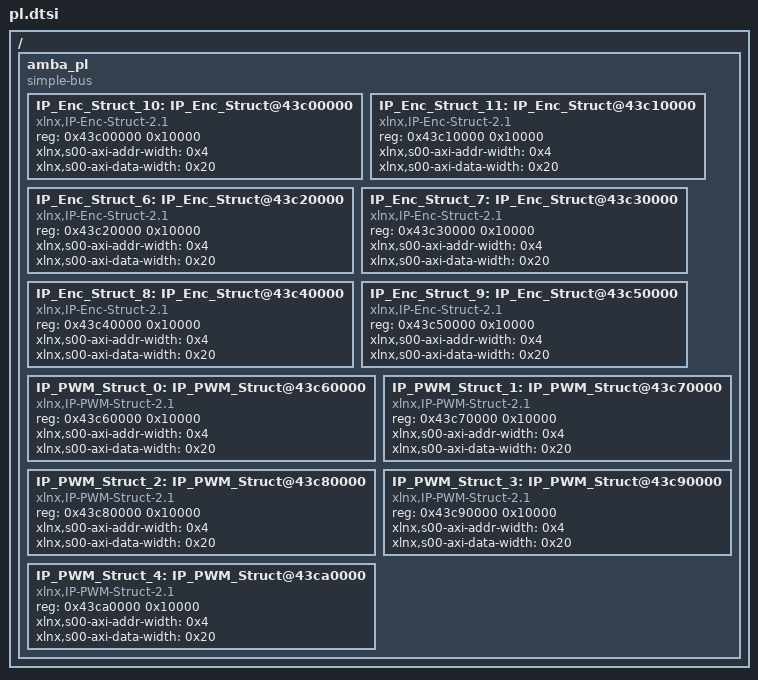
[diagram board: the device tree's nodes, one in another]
/*
 * CAUTION: This file is automatically generated by Xilinx.
 * Version:  
 * Today is: Wed Aug 17 12:50:03 2016
*/


/ {
	amba_pl: amba_pl {
		#address-cells = <1>;
		#size-cells = <1>;
		compatible = "simple-bus";
		ranges ;
		IP_Enc_Struct_10: IP_Enc_Struct@43c00000 {
			compatible = "xlnx,IP-Enc-Struct-2.1";
			reg = <0x43c00000 0x10000>;
			xlnx,s00-axi-addr-width = <0x4>;
			xlnx,s00-axi-data-width = <0x20>;
		};
		IP_Enc_Struct_11: IP_Enc_Struct@43c10000 {
			compatible = "xlnx,IP-Enc-Struct-2.1";
			reg = <0x43c10000 0x10000>;
			xlnx,s00-axi-addr-width = <0x4>;
			xlnx,s00-axi-data-width = <0x20>;
		};
		IP_Enc_Struct_6: IP_Enc_Struct@43c20000 {
			compatible = "xlnx,IP-Enc-Struct-2.1";
			reg = <0x43c20000 0x10000>;
			xlnx,s00-axi-addr-width = <0x4>;
			xlnx,s00-axi-data-width = <0x20>;
		};
		IP_Enc_Struct_7: IP_Enc_Struct@43c30000 {
			compatible = "xlnx,IP-Enc-Struct-2.1";
			reg = <0x43c30000 0x10000>;
			xlnx,s00-axi-addr-width = <0x4>;
			xlnx,s00-axi-data-width = <0x20>;
		};
		IP_Enc_Struct_8: IP_Enc_Struct@43c40000 {
			compatible = "xlnx,IP-Enc-Struct-2.1";
			reg = <0x43c40000 0x10000>;
			xlnx,s00-axi-addr-width = <0x4>;
			xlnx,s00-axi-data-width = <0x20>;
		};
		IP_Enc_Struct_9: IP_Enc_Struct@43c50000 {
			compatible = "xlnx,IP-Enc-Struct-2.1";
			reg = <0x43c50000 0x10000>;
			xlnx,s00-axi-addr-width = <0x4>;
			xlnx,s00-axi-data-width = <0x20>;
		};
		IP_PWM_Struct_0: IP_PWM_Struct@43c60000 {
			compatible = "xlnx,IP-PWM-Struct-2.1";
			reg = <0x43c60000 0x10000>;
			xlnx,s00-axi-addr-width = <0x4>;
			xlnx,s00-axi-data-width = <0x20>;
		};
		IP_PWM_Struct_1: IP_PWM_Struct@43c70000 {
			compatible = "xlnx,IP-PWM-Struct-2.1";
			reg = <0x43c70000 0x10000>;
			xlnx,s00-axi-addr-width = <0x4>;
			xlnx,s00-axi-data-width = <0x20>;
		};
		IP_PWM_Struct_2: IP_PWM_Struct@43c80000 {
			compatible = "xlnx,IP-PWM-Struct-2.1";
			reg = <0x43c80000 0x10000>;
			xlnx,s00-axi-addr-width = <0x4>;
			xlnx,s00-axi-data-width = <0x20>;
		};
		IP_PWM_Struct_3: IP_PWM_Struct@43c90000 {
			compatible = "xlnx,IP-PWM-Struct-2.1";
			reg = <0x43c90000 0x10000>;
			xlnx,s00-axi-addr-width = <0x4>;
			xlnx,s00-axi-data-width = <0x20>;
		};
		IP_PWM_Struct_4: IP_PWM_Struct@43ca0000 {
			compatible = "xlnx,IP-PWM-Struct-2.1";
			reg = <0x43ca0000 0x10000>;
			xlnx,s00-axi-addr-width = <0x4>;
			xlnx,s00-axi-data-width = <0x20>;
		};
	};
};
